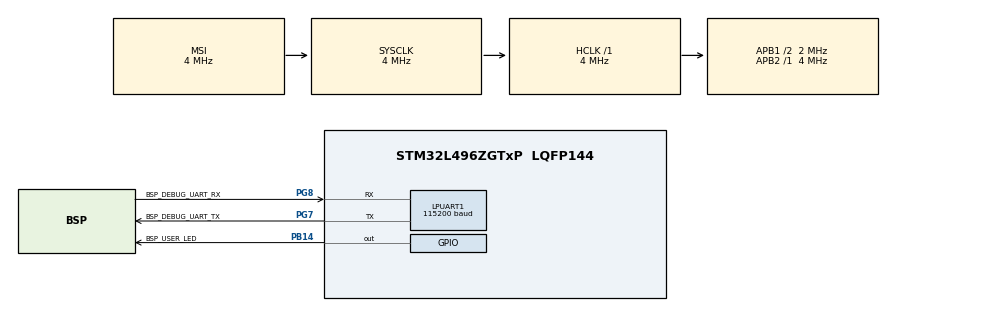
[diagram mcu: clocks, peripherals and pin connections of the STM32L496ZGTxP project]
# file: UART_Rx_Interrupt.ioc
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LPUART1.BaudRate=115200
LPUART1.WordLength=UART_WORDLENGTH_8B
Mcu.Family=STM32L4
Mcu.Name=STM32L496ZGTxP
Mcu.Package=LQFP144
NVIC.LPUART1_IRQn=true\:0\:0\:false\:false\:true\:true\:true\:true
NVIC.PriorityGroup=NVIC_PRIORITYGROUP_4
PB14.GPIO_Label=BSP_USER_LED
PB14.Signal=GPIO_Output
PG7.GPIO_Label=BSP_DEBUG_UART_TX
PG7.Mode=Asynchronous
PG7.Signal=LPUART1_TX
PG8.GPIO_Label=BSP_DEBUG_UART_RX
PG8.Mode=Asynchronous
PG8.Signal=LPUART1_RX
ProjectManager.HeapSize=0x200
ProjectManager.StackSize=0x400
ProjectManager.TargetToolchain=STM32CubeIDE
RCC.48MHZClocksFreq_Value=24000000
RCC.AHBFreq_Value=4000000
RCC.APB1CLKDivider=RCC_HCLK_DIV2
RCC.APB1Freq_Value=2000000
RCC.APB1TimFreq_Value=4000000
RCC.APB2Freq_Value=4000000
RCC.APB2TimFreq_Value=4000000
RCC.CortexFreq_Value=4000000
RCC.HCLKFreq_Value=4000000
RCC.HSE_VALUE=8000000
RCC.HSI48_VALUE=48000000
RCC.HSI_VALUE=16000000
RCC.LSE_VALUE=32768
RCC.MSI_VALUE=4000000
RCC.PLLMUL=RCC_PLL_MUL9
RCC.PRESCALERUSB=RCC_USBCLKSOURCE_PLL_DIV1_5
RCC.SYSCLKFreq_VALUE=4000000
RCC.SYSCLKSourceVirtual=RCC_SYSCLKSOURCE_PLLCLK
RCC.USBFreq_Value=16000000
RCC.VCOOutputFreq_Value=32000000
board=NUCLEO-L496ZG-P

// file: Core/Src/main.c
/* USER CODE BEGIN Header */
/**
  ******************************************************************************
  * @file           : main.c
  * @brief          : Main program body
  ******************************************************************************
  * @attention
  *
  * Copyright (c) 2024 STMicroelectronics.
  * All rights reserved.
  *
  * This software is licensed under terms that can be found in the LICENSE file
  * in the root directory of this software component.
  * If no LICENSE file comes with this software, it is provided AS-IS.
  *
  ******************************************************************************
  */
/* USER CODE END Header */
#include "main.h"
#include <stdio.h>
#include <string.h>

/* USER CODE BEGIN PM */
#define MAX_SIZE 10			//macro for size of buffer
#define NEWLINE_CHAR '\n'	//macro for newline character
#define RETURN_CHAR  '\r'	//macro for return carriage
/* USER CODE END PM */

UART_HandleTypeDef hlpuart1;

/* USER CODE BEGIN PV */
uint8_t rx_buffer[10];		//rx buffer
uint8_t print_buffer[10];	//buffer to print data on terminal
uint16_t Index = 0;			//index for buffer
/* USER CODE END PV */

void SystemClock_Config(void);
static void MX_GPIO_Init(void);
static void MX_LPUART1_UART_Init(void);
/* USER CODE BEGIN PFP */
void HAL_UART_RxCpltCallback(UART_HandleTypeDef *huart);
/* USER CODE END PFP */

int main(void)
{

  /* MCU Configuration--------------------------------------------------------*/

  /* Reset of all peripherals, Initializes the Flash interface and the Systick. */
  HAL_Init();

  /* Configure the system clock */
  SystemClock_Config();

  /* Initialize all configured peripherals */
  MX_GPIO_Init();
  MX_LPUART1_UART_Init();
  /* USER CODE BEGIN 2 */

  /* call the function to receive data into interrupt mode */
  HAL_UART_Receive_IT(&hlpuart1, rx_buffer, 1);

  /* USER CODE END 2 */

  /* Infinite loop */
  while (1)
  {

    /* USER CODE BEGIN 3 */

	  /* continuous operation */
	  HAL_GPIO_TogglePin(BSP_USER_LED_GPIO_Port, BSP_USER_LED_Pin);
	  HAL_Delay(500);
  }
  /* USER CODE END 3 */
}

void SystemClock_Config(void)
{
  RCC_OscInitTypeDef RCC_OscInitStruct = {0};
  RCC_ClkInitTypeDef RCC_ClkInitStruct = {0};

  /** Configure the main internal regulator output voltage
  */
  if (HAL_PWREx_ControlVoltageScaling(PWR_REGULATOR_VOLTAGE_SCALE1) != HAL_OK)
  {
    Error_Handler();
  }

  /** Initializes the RCC Oscillators according to the specified parameters
  * in the RCC_OscInitTypeDef structure.
  */
  RCC_OscInitStruct.OscillatorType = RCC_OSCILLATORTYPE_MSI;
  RCC_OscInitStruct.MSIState = RCC_MSI_ON;
  RCC_OscInitStruct.MSICalibrationValue = 0;
  RCC_OscInitStruct.MSIClockRange = RCC_MSIRANGE_6;
  RCC_OscInitStruct.PLL.PLLState = RCC_PLL_NONE;
  if (HAL_RCC_OscConfig(&RCC_OscInitStruct) != HAL_OK)
  {
    Error_Handler();
  }

  /** Initializes the CPU, AHB and APB buses clocks
  */
  RCC_ClkInitStruct.ClockType = RCC_CLOCKTYPE_HCLK|RCC_CLOCKTYPE_SYSCLK
                              |RCC_CLOCKTYPE_PCLK1|RCC_CLOCKTYPE_PCLK2;
  RCC_ClkInitStruct.SYSCLKSource = RCC_SYSCLKSOURCE_MSI;
  RCC_ClkInitStruct.AHBCLKDivider = RCC_SYSCLK_DIV1;
  RCC_ClkInitStruct.APB1CLKDivider = RCC_HCLK_DIV2;
  RCC_ClkInitStruct.APB2CLKDivider = RCC_HCLK_DIV1;

  if (HAL_RCC_ClockConfig(&RCC_ClkInitStruct, FLASH_LATENCY_0) != HAL_OK)
  {
    Error_Handler();
  }
}

static void MX_LPUART1_UART_Init(void)
{

  hlpuart1.Instance = LPUART1;
  hlpuart1.Init.BaudRate = 115200;
  hlpuart1.Init.WordLength = UART_WORDLENGTH_8B;
  hlpuart1.Init.StopBits = UART_STOPBITS_1;
  hlpuart1.Init.Parity = UART_PARITY_NONE;
  hlpuart1.Init.Mode = UART_MODE_TX_RX;
  hlpuart1.Init.HwFlowCtl = UART_HWCONTROL_NONE;
  hlpuart1.Init.OneBitSampling = UART_ONE_BIT_SAMPLE_DISABLE;
  hlpuart1.AdvancedInit.AdvFeatureInit = UART_ADVFEATURE_NO_INIT;
  if (HAL_UART_Init(&hlpuart1) != HAL_OK)
  {
    Error_Handler();
  }

}

static void MX_GPIO_Init(void)
{
  GPIO_InitTypeDef GPIO_InitStruct = {0};

  /* GPIO Ports Clock Enable */
  __HAL_RCC_GPIOB_CLK_ENABLE();
  __HAL_RCC_GPIOG_CLK_ENABLE();
  HAL_PWREx_EnableVddIO2();

  /*Configure GPIO pin Output Level */
  HAL_GPIO_WritePin(BSP_USER_LED_GPIO_Port, BSP_USER_LED_Pin, GPIO_PIN_RESET);

  /*Configure GPIO pin : BSP_USER_LED_Pin */
  GPIO_InitStruct.Pin = BSP_USER_LED_Pin;
  GPIO_InitStruct.Mode = GPIO_MODE_OUTPUT_PP;
  GPIO_InitStruct.Pull = GPIO_NOPULL;
  GPIO_InitStruct.Speed = GPIO_SPEED_FREQ_LOW;
  HAL_GPIO_Init(BSP_USER_LED_GPIO_Port, &GPIO_InitStruct);

}

/* USER CODE BEGIN 4 */
void HAL_UART_RxCpltCallback(UART_HandleTypeDef *huart)
{
	/* start the reception of data in interrupt mode again */
	HAL_UART_Receive_IT(&hlpuart1, rx_buffer, 1);
	if(rx_buffer[0]!= RETURN_CHAR && rx_buffer[0] != NEWLINE_CHAR)
	{
		print_buffer[Index] = rx_buffer[0];
		Index++;
	}
	/* print the buffer if rx_buffer encounters a newline character */
	else if (rx_buffer[0] == NEWLINE_CHAR)
	{
		printf("%s\r\n", print_buffer);	//print the data on the terminal

		/* Clear the buffer */
		memset(print_buffer, 0, MAX_SIZE);
		Index = 0;
  }
		/* If you want to print data using uart
		 * use below line */
//	HAL_UART_Transmit_IT(&hlpuart1, rx_buffer, 1);
}
/* USER CODE END 4 */

void Error_Handler(void)
{
  __disable_irq();
  while (1)
  {
  }
}
